# LPC804 register map
Vendor: nxp.com; File version: 1.0
CPU: CM0PLUS r0p0, little endian, no MPU, no FPU, VTOR, 2 interrupt priority bits
Registers are 32-bit, read-write, reset 0x0 unless marked. A register's access mark holds for its fields unless they carry their own. Offsets are from the block's base; [hi:lo] are bit positions; 'fields as' and 'values as' point back to an identical list.

## IOCON — LPC804 I/O pin configuration (IOCON)
Base 0x40044000
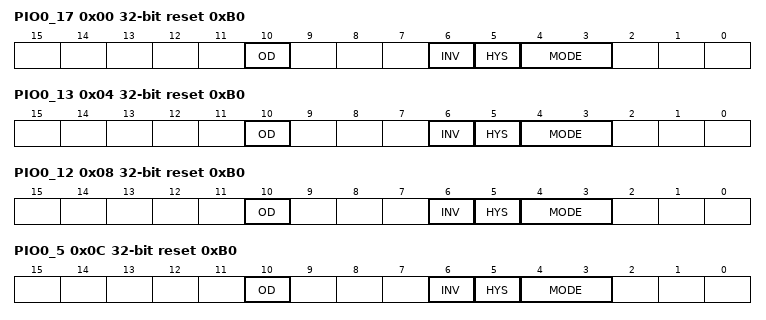
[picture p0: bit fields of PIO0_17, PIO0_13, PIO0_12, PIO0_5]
0x00 PIO0_17 reset 0xB0 — Digital I/O control for pins PIO0_17
  [10] OD — Open-drain mode.
    0=DISABLE; 1=ENABLED (Open-drain mode enabled. Remark: This is not a true open-drain mode.)
  [6] INV — Invert input
    0=NOT_INVERTED (Input not inverted (HIGH on pin reads as 1; LOW on pin reads as 0).); 1=INVERTED (Input inverted (HIGH on pin reads as 0, LOW on pin reads as 1).)
  [5] HYS — Hysteresis.
    0=DISABLE; 1=ENABLE
  [4:3] MODE — Selects function mode (on-chip pull-up/pull-down resistor control).
    0=INACTIVE (Inactive. Inactive (no pull-down/pull-up resistor enabled).); 1=PULL_DOWN (Pull-down. Pull-down resistor enabled.); 2=PULL_UP (Pull-up. Pull-up resistor enabled.); 3=REPEATER (Repeater. Repeater mode.)
0x04 PIO0_13 reset 0xB0 — Digital I/O control for pins PIO0_13
  fields as PIO0_17
0x08 PIO0_12 reset 0xB0 — Digital I/O control for pins PIO0_12
  fields as PIO0_17
0x0C PIO0_5 reset 0xB0 — Digital I/O control for pins PIO0_5
  fields as PIO0_17
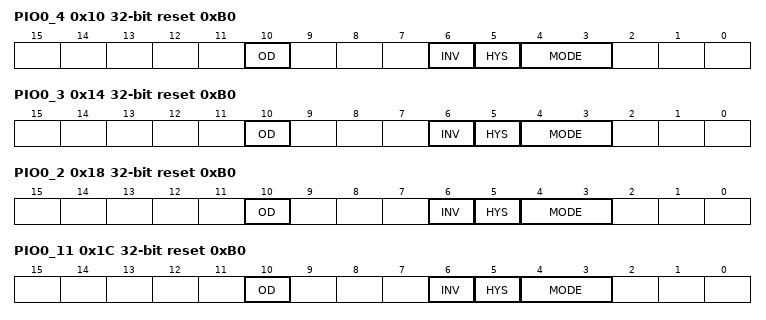
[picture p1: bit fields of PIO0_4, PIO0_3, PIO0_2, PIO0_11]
0x10 PIO0_4 reset 0xB0 — Digital I/O control for pins PIO0_4
  fields as PIO0_17
0x14 PIO0_3 reset 0xB0 — Digital I/O control for pins PIO0_3
  fields as PIO0_17
0x18 PIO0_2 reset 0xB0 — Digital I/O control for pins PIO0_2
  fields as PIO0_17
0x1C PIO0_11 reset 0xB0 — Digital I/O control for pins PIO0_11
  fields as PIO0_17
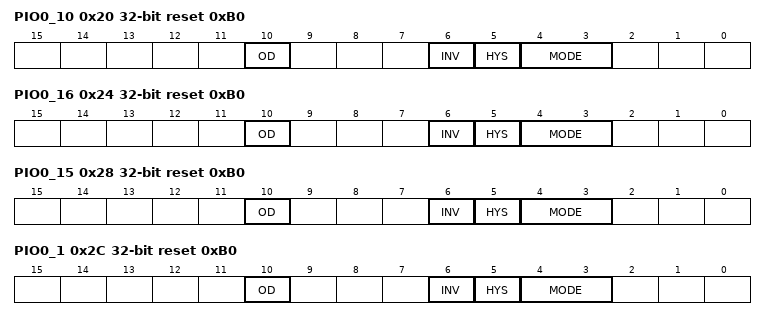
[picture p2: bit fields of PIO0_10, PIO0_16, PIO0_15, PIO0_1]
0x20 PIO0_10 reset 0xB0 — Digital I/O control for pins PIO0_10
  fields as PIO0_17
0x24 PIO0_16 reset 0xB0 — Digital I/O control for pins PIO0_16
  fields as PIO0_17
0x28 PIO0_15 reset 0xB0 — Digital I/O control for pins PIO0_15
  fields as PIO0_17
0x2C PIO0_1 reset 0xB0 — Digital I/O control for pins PIO0_1
  fields as PIO0_17
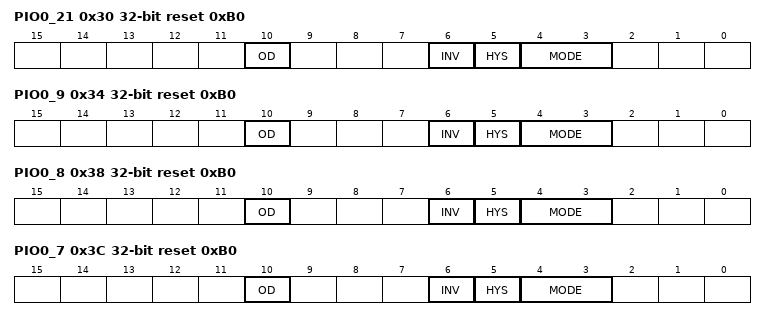
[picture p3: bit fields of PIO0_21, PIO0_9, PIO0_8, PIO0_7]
0x30 PIO0_21 reset 0xB0 — Digital I/O control for pins PIO0_21
  fields as PIO0_17
0x34 PIO0_9 reset 0xB0 — Digital I/O control for pins PIO0_9
  fields as PIO0_17
0x38 PIO0_8 reset 0xB0 — Digital I/O control for pins PIO0_8
  fields as PIO0_17
0x3C PIO0_7 reset 0xB0 — Digital I/O control for pins PIO0_7
  fields as PIO0_17
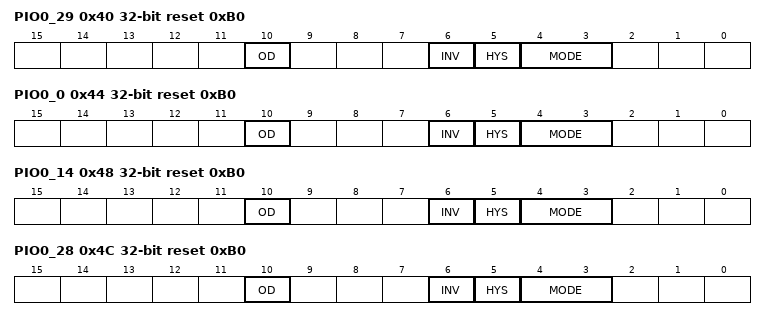
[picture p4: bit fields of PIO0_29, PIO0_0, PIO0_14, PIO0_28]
0x40 PIO0_29 reset 0xB0 — Digital I/O control for pins PIO0_29
  fields as PIO0_17
0x44 PIO0_0 reset 0xB0 — Digital I/O control for pins PIO0_0
  fields as PIO0_17
0x48 PIO0_14 reset 0xB0 — Digital I/O control for pins PIO0_14
  fields as PIO0_17
0x4C PIO0_28 reset 0xB0 — Digital I/O control for pins PIO0_28
  fields as PIO0_17
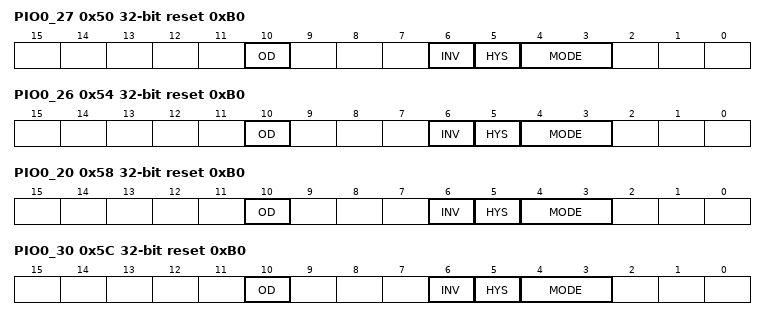
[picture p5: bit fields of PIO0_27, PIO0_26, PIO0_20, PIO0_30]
0x50 PIO0_27 reset 0xB0 — Digital I/O control for pins PIO0_27
  fields as PIO0_17
0x54 PIO0_26 reset 0xB0 — Digital I/O control for pins PIO0_26
  fields as PIO0_17
0x58 PIO0_20 reset 0xB0 — Digital I/O control for pins PIO0_20
  fields as PIO0_17
0x5C PIO0_30 reset 0xB0 — Digital I/O control for pins PIO0_30
  fields as PIO0_17
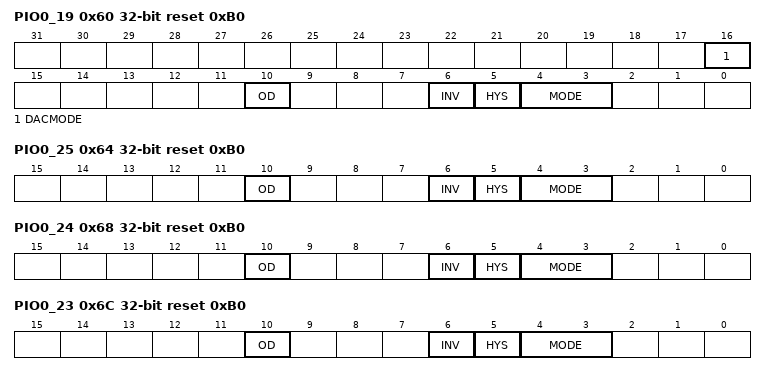
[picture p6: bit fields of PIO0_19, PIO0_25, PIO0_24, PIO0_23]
0x60 PIO0_19 reset 0xB0 — Digital I/O control for pins PIO0_19
  [16] DACMODE — DAC mode enable.
    0=DISABLE; 1=ENABLE
  [10] OD — Open-drain mode.
    values as PIO0_17.OD
  [6] INV — Invert input
    values as PIO0_17.INV
  [5] HYS — Hysteresis.
    0=DISABLE; 1=ENABLE
  [4:3] MODE — Selects function mode (on-chip pull-up/pull-down resistor control).
    values as PIO0_17.MODE
0x64 PIO0_25 reset 0xB0 — Digital I/O control for pins PIO0_25
  fields as PIO0_17
0x68 PIO0_24 reset 0xB0 — Digital I/O control for pins PIO0_24
  fields as PIO0_17
0x6C PIO0_23 reset 0xB0 — Digital I/O control for pins PIO0_23
  fields as PIO0_17
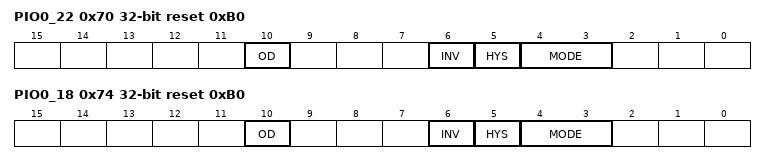
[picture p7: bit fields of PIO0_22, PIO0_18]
0x70 PIO0_22 reset 0xB0 — Digital I/O control for pins PIO0_22
  fields as PIO0_17
0x74 PIO0_18 reset 0xB0 — Digital I/O control for pins PIO0_18
  fields as PIO0_17

## CRC — LPC80X CRC engine
Base 0x50000000
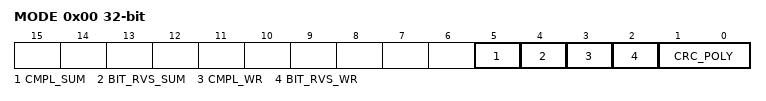
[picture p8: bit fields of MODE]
0x00 MODE — CRC mode register
  [5] CMPL_SUM — CRC sum complement: 1 = 1's complement for CRC_SUM 0 = No 1's complement for CRC_SUM
  [4] BIT_RVS_SUM — CRC sum bit order: 1 = Bit order reverse for CRC_SUM 0 = No bit order reverse for CRC_SUM
  [3] CMPL_WR — Data complement: 1 = 1's complement for CRC_WR_DATA 0 = No 1's complement for CRC_WR_DATA
  [2] BIT_RVS_WR — Data bit order: 1 = Bit order reverse for CRC_WR_DATA (per byte) 0 = No bit order reverse for CRC_WR_DATA (per byte)
  [1:0] CRC_POLY — CRC polynomial: 1X = CRC-32 polynomial 01 = CRC-16 polynomial 00 = CRC-CCITT polynomial
0x04 SEED reset 0xFFFF — CRC seed register
  [31:0] CRC_SEED — A write access to this register will load CRC seed value to CRC_SUM register with selected bit order and 1's complement pre-processes. A write access to this register will overrule the CRC calculation in progresses.
0x08 SUM ro reset 0xFFFF (SUM_WR_DATA view) — CRC checksum register
  [31:0] CRC_SUM — The most recent CRC sum can be read through this register with selected bit order and 1's complement post-processes.
0x08 WR_DATA wo reset not defined (SUM_WR_DATA view) — CRC data register
  [31:0] CRC_WR_DATA — Data written to this register will be taken to perform CRC calculation with selected bit order and 1's complement pre-process. Any write size 8, 16 or 32-bit are allowed and accept back-to-back transactions.
